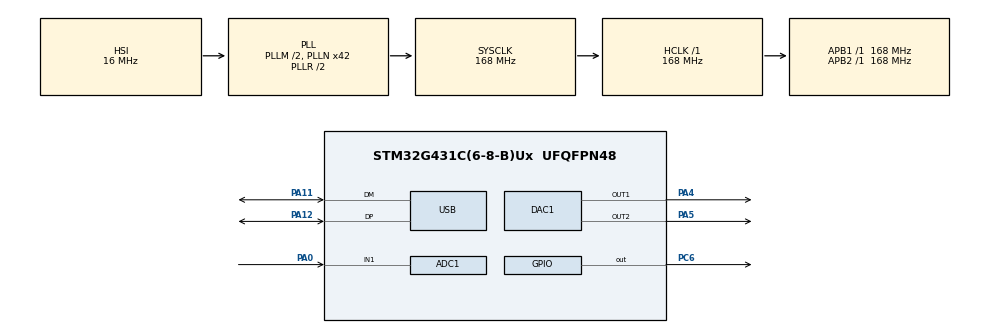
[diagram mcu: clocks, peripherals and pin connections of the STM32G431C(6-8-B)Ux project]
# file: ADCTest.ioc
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ADC1.Channel-0\#ChannelRegularConversion=ADC_CHANNEL_1
ADC1.ClockPrescaler=ADC_CLOCK_ASYNC_DIV32
ADC1.ContinuousConvMode=ENABLE
ADC1.EOCSelection=ADC_EOC_SINGLE_CONV
ADC1.NbrOfConversionFlag=1
ADC1.OffsetNumber-0\#ChannelRegularConversion=ADC_OFFSET_NONE
ADC1.Rank-0\#ChannelRegularConversion=1
ADC1.Resolution=ADC_RESOLUTION_12B
ADC1.SamplingTime-0\#ChannelRegularConversion=ADC_SAMPLETIME_12CYCLES_5
ADC1.master=1
DAC1.DAC_Channel-DAC_OUT2=DAC_CHANNEL_2
DAC1.DAC_DMADoubleDataMode-DAC_OUT1=DISABLE
DAC1.DAC_Trigger_OUT1-DAC_OUT1=DAC_TRIGGER_T2_TRGO
DAC1.DAC_Trigger_OUT2-DAC_OUT2=DAC_TRIGGER_T3_TRGO
Dma.ADC1.0.Direction=DMA_PERIPH_TO_MEMORY
Dma.ADC1.0.EventEnable=DISABLE
Dma.ADC1.0.Instance=DMA1_Channel1
Dma.ADC1.0.MemDataAlignment=DMA_MDATAALIGN_HALFWORD
Dma.ADC1.0.MemInc=DMA_MINC_ENABLE
Dma.ADC1.0.Mode=DMA_NORMAL
Dma.ADC1.0.PeriphDataAlignment=DMA_PDATAALIGN_HALFWORD
Dma.ADC1.0.PeriphInc=DMA_PINC_DISABLE
Dma.ADC1.0.Polarity=HAL_DMAMUX_REQ_GEN_RISING
Dma.ADC1.0.Priority=DMA_PRIORITY_HIGH
Dma.ADC1.0.RequestNumber=1
Dma.ADC1.0.SignalID=NONE
Dma.ADC1.0.SyncEnable=DISABLE
Dma.ADC1.0.SyncPolarity=HAL_DMAMUX_SYNC_NO_EVENT
Dma.ADC1.0.SyncRequestNumber=1
Dma.ADC1.0.SyncSignalID=NONE
Dma.DAC1_CH1.1.Direction=DMA_MEMORY_TO_PERIPH
Dma.DAC1_CH1.1.EventEnable=DISABLE
Dma.DAC1_CH1.1.Instance=DMA2_Channel1
Dma.DAC1_CH1.1.MemDataAlignment=DMA_MDATAALIGN_HALFWORD
Dma.DAC1_CH1.1.MemInc=DMA_MINC_ENABLE
Dma.DAC1_CH1.1.Mode=DMA_CIRCULAR
Dma.DAC1_CH1.1.PeriphDataAlignment=DMA_PDATAALIGN_WORD
Dma.DAC1_CH1.1.PeriphInc=DMA_PINC_DISABLE
Dma.DAC1_CH1.1.Polarity=HAL_DMAMUX_REQ_GEN_RISING
Dma.DAC1_CH1.1.Priority=DMA_PRIORITY_HIGH
Dma.DAC1_CH1.1.RequestNumber=1
Dma.DAC1_CH1.1.SignalID=NONE
Dma.DAC1_CH1.1.SyncEnable=DISABLE
Dma.DAC1_CH1.1.SyncPolarity=HAL_DMAMUX_SYNC_NO_EVENT
Dma.DAC1_CH1.1.SyncRequestNumber=1
Dma.DAC1_CH1.1.SyncSignalID=NONE
Dma.DAC1_CH2.2.Direction=DMA_MEMORY_TO_PERIPH
Dma.DAC1_CH2.2.EventEnable=DISABLE
Dma.DAC1_CH2.2.Instance=DMA2_Channel2
Dma.DAC1_CH2.2.MemDataAlignment=DMA_MDATAALIGN_HALFWORD
Dma.DAC1_CH2.2.MemInc=DMA_MINC_ENABLE
Dma.DAC1_CH2.2.Mode=DMA_CIRCULAR
Dma.DAC1_CH2.2.PeriphDataAlignment=DMA_PDATAALIGN_WORD
Dma.DAC1_CH2.2.PeriphInc=DMA_PINC_DISABLE
Dma.DAC1_CH2.2.Polarity=HAL_DMAMUX_REQ_GEN_RISING
Dma.DAC1_CH2.2.Priority=DMA_PRIORITY_MEDIUM
Dma.DAC1_CH2.2.RequestNumber=1
Dma.DAC1_CH2.2.SignalID=NONE
Dma.DAC1_CH2.2.SyncEnable=DISABLE
Dma.DAC1_CH2.2.SyncPolarity=HAL_DMAMUX_SYNC_NO_EVENT
Dma.DAC1_CH2.2.SyncRequestNumber=1
Dma.DAC1_CH2.2.SyncSignalID=NONE
Dma.Request0=ADC1
Dma.Request1=DAC1_CH1
Dma.Request2=DAC1_CH2
Mcu.Family=STM32G4
Mcu.Name=STM32G431C(6-8-B)Ux
Mcu.Package=UFQFPN48
NVIC.DMA1_Channel1_IRQn=true\:0\:0\:false\:false\:true\:false\:true\:true
NVIC.DMA2_Channel1_IRQn=true\:0\:0\:false\:false\:true\:false\:true\:true
NVIC.DMA2_Channel2_IRQn=true\:0\:0\:false\:false\:true\:false\:true\:true
NVIC.PriorityGroup=NVIC_PRIORITYGROUP_4
NVIC.USB_LP_IRQn=true\:0\:0\:false\:false\:true\:false\:true\:true
PA0.Mode=IN1-Single-Ended
PA0.Signal=ADC1_IN1
PA11.Mode=Device
PA11.Signal=USB_DM
PA12.Mode=Device
PA12.Signal=USB_DP
PA13.Mode=Serial_Wire
PA13.Signal=SYS_JTMS-SWDIO
PA14.Mode=Serial_Wire
PA14.Signal=SYS_JTCK-SWCLK
PA4.Signal=COMP_DAC11_group
PA5.Signal=COMP_DAC12_group
PC6.Signal=GPIO_Output
ProjectManager.HeapSize=0x200
ProjectManager.StackSize=0x400
ProjectManager.TargetToolchain=STM32CubeIDE
RCC.ADC12Freq_Value=168000000
RCC.AHBFreq_Value=168000000
RCC.APB1Freq_Value=168000000
RCC.APB1TimFreq_Value=168000000
RCC.APB2Freq_Value=168000000
RCC.APB2TimFreq_Value=168000000
RCC.CK48CLockSelection=RCC_USBCLKSOURCE_HSI48
RCC.CortexFreq_Value=168000000
RCC.EXTERNAL_CLOCK_VALUE=12288000
RCC.HCLKFreq_Value=168000000
RCC.HSE_VALUE=8000000
RCC.HSI48_VALUE=48000000
RCC.HSI_VALUE=16000000
RCC.LSE_VALUE=32768
RCC.PLLM=RCC_PLLM_DIV2
RCC.PLLN=42
RCC.PLLQ=RCC_PLLQ_DIV4
RCC.SYSCLKFreq_VALUE=168000000
RCC.SYSCLKSource=RCC_SYSCLKSOURCE_PLLCLK
RCC.USBFreq_Value=48000000
RCC.VCOOutputFreq_Value=336000000
SH.COMP_DAC11_group.0=DAC1_OUT1,DAC_OUT1
SH.COMP_DAC12_group.0=DAC1_OUT2,DAC_OUT2
TIM2.AutoReloadPreload=TIM_AUTORELOAD_PRELOAD_ENABLE
TIM2.PeriodNoDither=839
TIM2.TIM_MasterOutputTrigger=TIM_TRGO_UPDATE
TIM3.AutoReloadPreload=TIM_AUTORELOAD_PRELOAD_ENABLE
TIM3.PeriodNoDither=7635
TIM3.TIM_MasterOutputTrigger=TIM_TRGO_UPDATE
USB_DEVICE.CLASS_NAME_FS=CDC
USB_DEVICE.VirtualMode=Cdc
USB_DEVICE.VirtualModeFS=Cdc_FS
VP_FMAC_VS_FMAC.Mode=FMAC_Activate
VP_SYS_VS_DBSignals.Mode=DisableDeadBatterySignals
VP_TIM2_VS_ClockSourceINT.Mode=Internal
VP_TIM3_VS_ClockSourceINT.Mode=Internal
VP_USB_DEVICE_VS_USB_DEVICE_CDC_FS.Mode=CDC_FS
board=custom

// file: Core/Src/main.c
/* USER CODE BEGIN Header */
/* USER CODE END Header */
#include "main.h"
#include "usb_device.h"

/* USER CODE BEGIN Includes */
#include "startup.h"
#include "fmac_fir.h"
/* USER CODE END Includes */

ADC_HandleTypeDef hadc1;
DMA_HandleTypeDef hdma_adc1;

DAC_HandleTypeDef hdac1;
DMA_HandleTypeDef hdma_dac1_ch1;
DMA_HandleTypeDef hdma_dac1_ch2;

FMAC_HandleTypeDef hfmac;

TIM_HandleTypeDef htim2;
TIM_HandleTypeDef htim3;

void SystemClock_Config(void);
static void MX_GPIO_Init(void);
static void MX_DMA_Init(void);
static void MX_ADC1_Init(void);
static void MX_DAC1_Init(void);
static void MX_TIM2_Init(void);
static void MX_TIM3_Init(void);
static void MX_FMAC_Init(void);

int main(void)
{

  /* MCU Configuration--------------------------------------------------------*/

  /* Reset of all peripherals, Initializes the Flash interface and the Systick. */
  HAL_Init();

  /* Configure the system clock */
  SystemClock_Config();

  /* Initialize all configured peripherals */
  MX_GPIO_Init();
  MX_DMA_Init();
  MX_ADC1_Init();
  MX_DAC1_Init();
  MX_TIM2_Init();
  MX_TIM3_Init();
  MX_USB_Device_Init();
  MX_FMAC_Init();

  /* Infinite loop */
  /* USER CODE BEGIN 3 */

  fmac_fir_start(&hfmac);
  begin(&hadc1, &hdac1, &htim2, &hdac1, &htim3);
  /* USER CODE END 3 */
}

void SystemClock_Config(void)
{
  RCC_OscInitTypeDef RCC_OscInitStruct = {0};
  RCC_ClkInitTypeDef RCC_ClkInitStruct = {0};

  /** Configure the main internal regulator output voltage
  */
  HAL_PWREx_ControlVoltageScaling(PWR_REGULATOR_VOLTAGE_SCALE1_BOOST);

  /** Initializes the RCC Oscillators according to the specified parameters
  * in the RCC_OscInitTypeDef structure.
  */
  RCC_OscInitStruct.OscillatorType = RCC_OSCILLATORTYPE_HSI|RCC_OSCILLATORTYPE_HSI48;
  RCC_OscInitStruct.HSIState = RCC_HSI_ON;
  RCC_OscInitStruct.HSICalibrationValue = RCC_HSICALIBRATION_DEFAULT;
  RCC_OscInitStruct.HSI48State = RCC_HSI48_ON;
  RCC_OscInitStruct.PLL.PLLState = RCC_PLL_ON;
  RCC_OscInitStruct.PLL.PLLSource = RCC_PLLSOURCE_HSI;
  RCC_OscInitStruct.PLL.PLLM = RCC_PLLM_DIV2;
  RCC_OscInitStruct.PLL.PLLN = 42;
  RCC_OscInitStruct.PLL.PLLP = RCC_PLLP_DIV2;
  RCC_OscInitStruct.PLL.PLLQ = RCC_PLLQ_DIV4;
  RCC_OscInitStruct.PLL.PLLR = RCC_PLLR_DIV2;
  if (HAL_RCC_OscConfig(&RCC_OscInitStruct) != HAL_OK)
  {
    Error_Handler();
  }

  /** Initializes the CPU, AHB and APB buses clocks
  */
  RCC_ClkInitStruct.ClockType = RCC_CLOCKTYPE_HCLK|RCC_CLOCKTYPE_SYSCLK
                              |RCC_CLOCKTYPE_PCLK1|RCC_CLOCKTYPE_PCLK2;
  RCC_ClkInitStruct.SYSCLKSource = RCC_SYSCLKSOURCE_PLLCLK;
  RCC_ClkInitStruct.AHBCLKDivider = RCC_SYSCLK_DIV1;
  RCC_ClkInitStruct.APB1CLKDivider = RCC_HCLK_DIV1;
  RCC_ClkInitStruct.APB2CLKDivider = RCC_HCLK_DIV1;

  if (HAL_RCC_ClockConfig(&RCC_ClkInitStruct, FLASH_LATENCY_4) != HAL_OK)
  {
    Error_Handler();
  }
}

static void MX_ADC1_Init(void)
{

  ADC_MultiModeTypeDef multimode = {0};
  ADC_ChannelConfTypeDef sConfig = {0};

  /** Common config
  */
  hadc1.Instance = ADC1;
  hadc1.Init.ClockPrescaler = ADC_CLOCK_ASYNC_DIV32;
  hadc1.Init.Resolution = ADC_RESOLUTION_12B;
  hadc1.Init.DataAlign = ADC_DATAALIGN_RIGHT;
  hadc1.Init.GainCompensation = 0;
  hadc1.Init.ScanConvMode = ADC_SCAN_DISABLE;
  hadc1.Init.EOCSelection = ADC_EOC_SINGLE_CONV;
  hadc1.Init.LowPowerAutoWait = DISABLE;
  hadc1.Init.ContinuousConvMode = ENABLE;
  hadc1.Init.NbrOfConversion = 1;
  hadc1.Init.DiscontinuousConvMode = DISABLE;
  hadc1.Init.ExternalTrigConv = ADC_SOFTWARE_START;
  hadc1.Init.ExternalTrigConvEdge = ADC_EXTERNALTRIGCONVEDGE_NONE;
  hadc1.Init.DMAContinuousRequests = DISABLE;
  hadc1.Init.Overrun = ADC_OVR_DATA_PRESERVED;
  hadc1.Init.OversamplingMode = DISABLE;
  if (HAL_ADC_Init(&hadc1) != HAL_OK)
  {
    Error_Handler();
  }

  /** Configure the ADC multi-mode
  */
  multimode.Mode = ADC_MODE_INDEPENDENT;
  if (HAL_ADCEx_MultiModeConfigChannel(&hadc1, &multimode) != HAL_OK)
  {
    Error_Handler();
  }

  /** Configure Regular Channel
  */
  sConfig.Channel = ADC_CHANNEL_1;
  sConfig.Rank = ADC_REGULAR_RANK_1;
  sConfig.SamplingTime = ADC_SAMPLETIME_12CYCLES_5;
  sConfig.SingleDiff = ADC_SINGLE_ENDED;
  sConfig.OffsetNumber = ADC_OFFSET_NONE;
  sConfig.Offset = 0;
  if (HAL_ADC_ConfigChannel(&hadc1, &sConfig) != HAL_OK)
  {
    Error_Handler();
  }

}

static void MX_DAC1_Init(void)
{

  DAC_ChannelConfTypeDef sConfig = {0};

  /** DAC Initialization
  */
  hdac1.Instance = DAC1;
  if (HAL_DAC_Init(&hdac1) != HAL_OK)
  {
    Error_Handler();
  }

  /** DAC channel OUT1 config
  */
  sConfig.DAC_HighFrequency = DAC_HIGH_FREQUENCY_INTERFACE_MODE_AUTOMATIC;
  sConfig.DAC_DMADoubleDataMode = DISABLE;
  sConfig.DAC_SignedFormat = DISABLE;
  sConfig.DAC_SampleAndHold = DAC_SAMPLEANDHOLD_DISABLE;
  sConfig.DAC_Trigger = DAC_TRIGGER_T2_TRGO;
  sConfig.DAC_Trigger2 = DAC_TRIGGER_NONE;
  sConfig.DAC_OutputBuffer = DAC_OUTPUTBUFFER_ENABLE;
  sConfig.DAC_ConnectOnChipPeripheral = DAC_CHIPCONNECT_EXTERNAL;
  sConfig.DAC_UserTrimming = DAC_TRIMMING_FACTORY;
  if (HAL_DAC_ConfigChannel(&hdac1, &sConfig, DAC_CHANNEL_1) != HAL_OK)
  {
    Error_Handler();
  }

  /** DAC channel OUT2 config
  */
  sConfig.DAC_Trigger = DAC_TRIGGER_T3_TRGO;
  if (HAL_DAC_ConfigChannel(&hdac1, &sConfig, DAC_CHANNEL_2) != HAL_OK)
  {
    Error_Handler();
  }

}

static void MX_FMAC_Init(void)
{

  hfmac.Instance = FMAC;
  if (HAL_FMAC_Init(&hfmac) != HAL_OK)
  {
    Error_Handler();
  }

}

static void MX_TIM2_Init(void)
{

  TIM_ClockConfigTypeDef sClockSourceConfig = {0};
  TIM_MasterConfigTypeDef sMasterConfig = {0};

  htim2.Instance = TIM2;
  htim2.Init.Prescaler = 0;
  htim2.Init.CounterMode = TIM_COUNTERMODE_UP;
  htim2.Init.Period = 839;
  htim2.Init.ClockDivision = TIM_CLOCKDIVISION_DIV1;
  htim2.Init.AutoReloadPreload = TIM_AUTORELOAD_PRELOAD_ENABLE;
  if (HAL_TIM_Base_Init(&htim2) != HAL_OK)
  {
    Error_Handler();
  }
  sClockSourceConfig.ClockSource = TIM_CLOCKSOURCE_INTERNAL;
  if (HAL_TIM_ConfigClockSource(&htim2, &sClockSourceConfig) != HAL_OK)
  {
    Error_Handler();
  }
  sMasterConfig.MasterOutputTrigger = TIM_TRGO_UPDATE;
  sMasterConfig.MasterSlaveMode = TIM_MASTERSLAVEMODE_DISABLE;
  if (HAL_TIMEx_MasterConfigSynchronization(&htim2, &sMasterConfig) != HAL_OK)
  {
    Error_Handler();
  }

}

static void MX_TIM3_Init(void)
{

  TIM_ClockConfigTypeDef sClockSourceConfig = {0};
  TIM_MasterConfigTypeDef sMasterConfig = {0};

  htim3.Instance = TIM3;
  htim3.Init.Prescaler = 0;
  htim3.Init.CounterMode = TIM_COUNTERMODE_UP;
  htim3.Init.Period = 7635;
  htim3.Init.ClockDivision = TIM_CLOCKDIVISION_DIV1;
  htim3.Init.AutoReloadPreload = TIM_AUTORELOAD_PRELOAD_ENABLE;
  if (HAL_TIM_Base_Init(&htim3) != HAL_OK)
  {
    Error_Handler();
  }
  sClockSourceConfig.ClockSource = TIM_CLOCKSOURCE_INTERNAL;
  if (HAL_TIM_ConfigClockSource(&htim3, &sClockSourceConfig) != HAL_OK)
  {
    Error_Handler();
  }
  sMasterConfig.MasterOutputTrigger = TIM_TRGO_UPDATE;
  sMasterConfig.MasterSlaveMode = TIM_MASTERSLAVEMODE_DISABLE;
  if (HAL_TIMEx_MasterConfigSynchronization(&htim3, &sMasterConfig) != HAL_OK)
  {
    Error_Handler();
  }

}

static void MX_DMA_Init(void)
{

  /* DMA controller clock enable */
  __HAL_RCC_DMAMUX1_CLK_ENABLE();
  __HAL_RCC_DMA1_CLK_ENABLE();
  __HAL_RCC_DMA2_CLK_ENABLE();

  /* DMA interrupt init */
  /* DMA1_Channel1_IRQn interrupt configuration */
  HAL_NVIC_SetPriority(DMA1_Channel1_IRQn, 0, 0);
  HAL_NVIC_EnableIRQ(DMA1_Channel1_IRQn);
  /* DMA2_Channel1_IRQn interrupt configuration */
  HAL_NVIC_SetPriority(DMA2_Channel1_IRQn, 0, 0);
  HAL_NVIC_EnableIRQ(DMA2_Channel1_IRQn);
  /* DMA2_Channel2_IRQn interrupt configuration */
  HAL_NVIC_SetPriority(DMA2_Channel2_IRQn, 0, 0);
  HAL_NVIC_EnableIRQ(DMA2_Channel2_IRQn);

}

static void MX_GPIO_Init(void)
{
  GPIO_InitTypeDef GPIO_InitStruct = {0};

  /* GPIO Ports Clock Enable */
  __HAL_RCC_GPIOA_CLK_ENABLE();
  __HAL_RCC_GPIOC_CLK_ENABLE();

  /*Configure GPIO pin Output Level */
  HAL_GPIO_WritePin(GPIOC, GPIO_PIN_6, GPIO_PIN_RESET);

  /*Configure GPIO pin : PC6 */
  GPIO_InitStruct.Pin = GPIO_PIN_6;
  GPIO_InitStruct.Mode = GPIO_MODE_OUTPUT_PP;
  GPIO_InitStruct.Pull = GPIO_NOPULL;
  GPIO_InitStruct.Speed = GPIO_SPEED_FREQ_LOW;
  HAL_GPIO_Init(GPIOC, &GPIO_InitStruct);

}

void Error_Handler(void)
{
}
